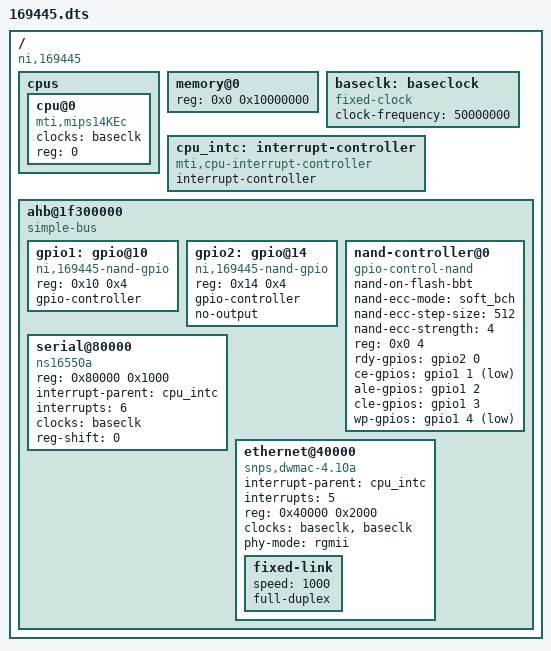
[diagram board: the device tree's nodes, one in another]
/dts-v1/;
#include <dt-bindings/gpio/gpio.h>

/ {
	#address-cells = <1>;
	#size-cells = <1>;
	compatible = "ni,169445";

	cpus {
		#address-cells = <1>;
		#size-cells = <0>;
		cpu@0 {
			device_type = "cpu";
			compatible = "mti,mips14KEc";
			clocks = <&baseclk>;
			reg = <0>;
		};
	};

	memory@0 {
		device_type = "memory";
		reg = <0x0 0x10000000>;
	};

	baseclk: baseclock {
		compatible = "fixed-clock";
		#clock-cells = <0>;
		clock-frequency = <50000000>;
	};

	cpu_intc: interrupt-controller {
		#address-cells = <0>;
		compatible = "mti,cpu-interrupt-controller";
		interrupt-controller;
		#interrupt-cells = <1>;
	};

	ahb@1f300000 {
		compatible = "simple-bus";
		#address-cells = <1>;
		#size-cells = <1>;
		ranges = <0x0 0x1f300000 0x80FFF>;

		gpio1: gpio@10 {
			compatible = "ni,169445-nand-gpio";
			reg = <0x10 0x4>;
			reg-names = "dat";
			gpio-controller;
			#gpio-cells = <2>;
		};

		gpio2: gpio@14 {
			compatible = "ni,169445-nand-gpio";
			reg = <0x14 0x4>;
			reg-names = "dat";
			gpio-controller;
			#gpio-cells = <2>;
			no-output;
		};

		nand-controller@0 {
			compatible = "gpio-control-nand";
			nand-on-flash-bbt;
			nand-ecc-mode = "soft_bch";
			nand-ecc-step-size = <512>;
			nand-ecc-strength = <4>;
			reg = <0x0 4>;
			rdy-gpios = <&gpio2 0 GPIO_ACTIVE_HIGH>;
			ce-gpios = <&gpio1 1 GPIO_ACTIVE_LOW>;
			ale-gpios = <&gpio1 2 GPIO_ACTIVE_HIGH>;
			cle-gpios = <&gpio1 3 GPIO_ACTIVE_HIGH>;
			wp-gpios = <&gpio1 4 GPIO_ACTIVE_LOW>;
		};

		serial@80000 {
			compatible = "ns16550a";
			reg = <0x80000 0x1000>;
			interrupt-parent = <&cpu_intc>;
			interrupts = <6>;
			clocks = <&baseclk>;
			reg-shift = <0>;
		};

		ethernet@40000 {
			compatible = "snps,dwmac-4.10a";
			interrupt-parent = <&cpu_intc>;
			interrupts = <5>;
			interrupt-names = "macirq";
			reg = <0x40000 0x2000>;
			clock-names = "stmmaceth", "pclk";
			clocks = <&baseclk>, <&baseclk>;

			phy-mode = "rgmii";

			fixed-link {
				speed = <1000>;
				full-duplex;
			};
		};
	};
};
